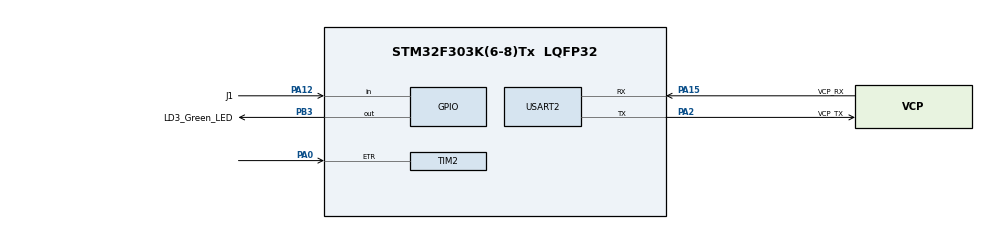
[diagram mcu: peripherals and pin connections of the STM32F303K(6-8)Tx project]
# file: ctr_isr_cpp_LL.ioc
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Mcu.Family=STM32F3
Mcu.Name=STM32F303K(6-8)Tx
Mcu.Package=LQFP32
NVIC.PriorityGroup=NVIC_PRIORITYGROUP_4
NVIC.TIM2_IRQn=true\:0\:0\:false\:false\:true\:true\:true
PA0.GPIO_PuPd=GPIO_PULLDOWN
PA0.Signal=S_TIM2_CH1_ETR
PA12.GPIO_Label=J1
PA12.GPIO_PuPd=GPIO_PULLUP
PA12.Signal=GPIO_Input
PA13.GPIO_Label=SWDIO
PA13.Mode=Serial_Wire
PA13.Signal=SYS_JTMS-SWDIO
PA14.GPIO_Label=SWCLK
PA14.Mode=Serial_Wire
PA14.Signal=SYS_JTCK-SWCLK
PA15.GPIO_Label=VCP_RX
PA15.Mode=Asynchronous
PA15.Signal=USART2_RX
PA2.GPIO_Label=VCP_TX
PA2.Mode=Asynchronous
PA2.Signal=USART2_TX
PB3.GPIO_Label=LD3_Green_LED
PB3.GPIO_Speed=GPIO_SPEED_FREQ_HIGH
PB3.Signal=GPIO_Output
PF0\ /\ OSC_IN.GPIO_Label=MCO
PF0\ /\ OSC_IN.Mode=HSE-External-Clock-Source
PF0\ /\ OSC_IN.Signal=RCC_OSC_IN
ProjectManager.HeapSize=0x200
ProjectManager.StackSize=0x400
ProjectManager.TargetToolchain=STM32CubeIDE
RCC.AHBFreq_Value=8000000
RCC.APB1Freq_Value=8000000
RCC.APB2Freq_Value=8000000
RCC.CortexFreq_Value=8000000
RCC.HSE_VALUE=8000000
RCC.HSI_VALUE=8000000
RCC.SYSCLKFreq_VALUE=8000000
SH.S_TIM2_CH1_ETR.0=TIM2_ETR,ClockSourceETR_Mode2
TIM2.ClockFilter=15
TIM2.Period=5
USART2.VirtualMode-Asynchronous=VM_ASYNC
board=NUCLEO-F303K8

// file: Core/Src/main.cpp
/* USER CODE BEGIN Header */
/**
  ******************************************************************************
  * @file           : main.cpp
  * @brief          : Main program body
  ******************************************************************************
  * @attention
  *
  * <h2><center>&copy; Copyright (c) 2020 STMicroelectronics.
  * All rights reserved.</center></h2>
  *
  * This software component is licensed by ST under BSD 3-Clause license,
  * the "License"; You may not use this file except in compliance with the
  * License. You may obtain a copy of the License at:
  *                        opensource.org/licenses/BSD-3-Clause
  *
  ******************************************************************************
  Use TIM2 to count a push-button connected between PA0 (called TIM2_ETR) and 3V3.
  PA0 is configured with a pull down.
  Green LED blinks but the blink rate toggles upon each TIM2 interrupt.
  TIM2 interrupt is called after 5 button presses.
  To debounce the button, LL_TIM_ETR_FILTER_FDIV32_N8 is used.
  No HAL - all LL (Low Level).
  */
/* USER CODE END Header */
#include "main.h"

/* USER CODE BEGIN PV */
unsigned ms_cnt;
unsigned tim2_int_cnt;
/* USER CODE END PV */

void SystemClock_Config(void);
static void MX_GPIO_Init(void);
static void MX_USART2_UART_Init(void);
static void MX_TIM2_Init(void);

/* USER CODE BEGIN 0 */
extern "C" void TIM2_IRQHandler(void)
{
  tim2_int_cnt++;
  TIM2->SR   &= ~TIM_SR_UIF;     // Clear prior interrupt
}

/* USER CODE END 0 */

int main(void)
{

  /* MCU Configuration--------------------------------------------------------*/

  /* Reset of all peripherals, Initializes the Flash interface and the Systick. */

  LL_APB2_GRP1_EnableClock(LL_APB2_GRP1_PERIPH_SYSCFG);
  LL_APB1_GRP1_EnableClock(LL_APB1_GRP1_PERIPH_PWR);

  NVIC_SetPriorityGrouping(NVIC_PRIORITYGROUP_4);

  /* System interrupt init*/

  /* Configure the system clock */
  SystemClock_Config();

  /* Initialize all configured peripherals */
  MX_GPIO_Init();
  MX_USART2_UART_Init();
  MX_TIM2_Init();
  /* USER CODE BEGIN 2 */
  SysTick->CTRL |= SysTick_CTRL_TICKINT_Msk;

  //
  // TIM2 setup
  //
  TIM2->ARR   = 5 - 1;           // Set count threshold of 5.
  TIM2->CR1  |= TIM_CR1_CEN;     // Counter enable
  TIM2->SR   &= ~TIM_SR_UIF;     // Clear prior interrupt
  TIM2->DIER |= TIM_DIER_UIE;    // Enable interrupt.
  /* USER CODE END 2 */

  /* Infinite loop */
  /* USER CODE BEGIN WHILE */
  while (1)
  {
	bool b = tim2_int_cnt & 1; // 0!=(TIM2_ETR_GPIO_Port->IDR & TIM2_ETR_Pin);
	uint32_t x = ms_cnt >> (b ? 5 : 9);
    (x & 1 ? LD3_Green_LED_GPIO_Port->BSRR : LD3_Green_LED_GPIO_Port->BRR) = LD3_Green_LED_Pin;
    /* USER CODE END WHILE */

  }
}

void SystemClock_Config(void)
{
  LL_FLASH_SetLatency(LL_FLASH_LATENCY_0);
  while(LL_FLASH_GetLatency()!= LL_FLASH_LATENCY_0)
  {
  }
  LL_RCC_HSI_Enable();

   /* Wait till HSI is ready */
  while(LL_RCC_HSI_IsReady() != 1)
  {

  }
  LL_RCC_HSI_SetCalibTrimming(16);
  LL_RCC_SetAHBPrescaler(LL_RCC_SYSCLK_DIV_1);
  LL_RCC_SetAPB1Prescaler(LL_RCC_APB1_DIV_1);
  LL_RCC_SetAPB2Prescaler(LL_RCC_APB1_DIV_1);
  LL_RCC_SetSysClkSource(LL_RCC_SYS_CLKSOURCE_HSI);

   /* Wait till System clock is ready */
  while(LL_RCC_GetSysClkSource() != LL_RCC_SYS_CLKSOURCE_STATUS_HSI)
  {

  }
  LL_Init1msTick(8000000);
  LL_SetSystemCoreClock(8000000);
}

static void MX_TIM2_Init(void)
{

  LL_TIM_InitTypeDef TIM_InitStruct = {0};

  LL_GPIO_InitTypeDef GPIO_InitStruct = {0};

  /* Peripheral clock enable */
  LL_APB1_GRP1_EnableClock(LL_APB1_GRP1_PERIPH_TIM2);

  LL_AHB1_GRP1_EnableClock(LL_AHB1_GRP1_PERIPH_GPIOA);
  /**TIM2 GPIO Configuration
  PA0   ------> TIM2_ETR
  */
  GPIO_InitStruct.Pin = LL_GPIO_PIN_0;
  GPIO_InitStruct.Mode = LL_GPIO_MODE_ALTERNATE;
  GPIO_InitStruct.Speed = LL_GPIO_SPEED_FREQ_LOW;
  GPIO_InitStruct.OutputType = LL_GPIO_OUTPUT_PUSHPULL;
  GPIO_InitStruct.Pull = LL_GPIO_PULL_DOWN;
  GPIO_InitStruct.Alternate = LL_GPIO_AF_1;
  LL_GPIO_Init(GPIOA, &GPIO_InitStruct);

  /* TIM2 interrupt Init */
  NVIC_SetPriority(TIM2_IRQn, NVIC_EncodePriority(NVIC_GetPriorityGrouping(),0, 0));
  NVIC_EnableIRQ(TIM2_IRQn);

  TIM_InitStruct.Prescaler = 0;
  TIM_InitStruct.CounterMode = LL_TIM_COUNTERMODE_UP;
  TIM_InitStruct.Autoreload = 5;
  TIM_InitStruct.ClockDivision = LL_TIM_CLOCKDIVISION_DIV1;
  LL_TIM_Init(TIM2, &TIM_InitStruct);
  LL_TIM_DisableARRPreload(TIM2);
  LL_TIM_ConfigETR(TIM2, LL_TIM_ETR_POLARITY_NONINVERTED, LL_TIM_ETR_PRESCALER_DIV1, LL_TIM_ETR_FILTER_FDIV32_N8);
  LL_TIM_SetClockSource(TIM2, LL_TIM_CLOCKSOURCE_EXT_MODE2);
  LL_TIM_SetTriggerOutput(TIM2, LL_TIM_TRGO_RESET);
  LL_TIM_DisableMasterSlaveMode(TIM2);

}

static void MX_USART2_UART_Init(void)
{

  LL_USART_InitTypeDef USART_InitStruct = {0};

  LL_GPIO_InitTypeDef GPIO_InitStruct = {0};

  /* Peripheral clock enable */
  LL_APB1_GRP1_EnableClock(LL_APB1_GRP1_PERIPH_USART2);

  LL_AHB1_GRP1_EnableClock(LL_AHB1_GRP1_PERIPH_GPIOA);
  /**USART2 GPIO Configuration
  PA2   ------> USART2_TX
  PA15   ------> USART2_RX
  */
  GPIO_InitStruct.Pin = VCP_TX_Pin|VCP_RX_Pin;
  GPIO_InitStruct.Mode = LL_GPIO_MODE_ALTERNATE;
  GPIO_InitStruct.Speed = LL_GPIO_SPEED_FREQ_HIGH;
  GPIO_InitStruct.OutputType = LL_GPIO_OUTPUT_PUSHPULL;
  GPIO_InitStruct.Pull = LL_GPIO_PULL_NO;
  GPIO_InitStruct.Alternate = LL_GPIO_AF_7;
  LL_GPIO_Init(GPIOA, &GPIO_InitStruct);

  USART_InitStruct.BaudRate = 38400;
  USART_InitStruct.DataWidth = LL_USART_DATAWIDTH_8B;
  USART_InitStruct.StopBits = LL_USART_STOPBITS_1;
  USART_InitStruct.Parity = LL_USART_PARITY_NONE;
  USART_InitStruct.TransferDirection = LL_USART_DIRECTION_TX_RX;
  USART_InitStruct.HardwareFlowControl = LL_USART_HWCONTROL_NONE;
  USART_InitStruct.OverSampling = LL_USART_OVERSAMPLING_16;
  LL_USART_Init(USART2, &USART_InitStruct);
  LL_USART_DisableIT_CTS(USART2);
  LL_USART_ConfigAsyncMode(USART2);
  LL_USART_Enable(USART2);

}

static void MX_GPIO_Init(void)
{
  LL_GPIO_InitTypeDef GPIO_InitStruct = {0};

  /* GPIO Ports Clock Enable */
  LL_AHB1_GRP1_EnableClock(LL_AHB1_GRP1_PERIPH_GPIOF);
  LL_AHB1_GRP1_EnableClock(LL_AHB1_GRP1_PERIPH_GPIOA);
  LL_AHB1_GRP1_EnableClock(LL_AHB1_GRP1_PERIPH_GPIOB);

  /**/
  LL_GPIO_ResetOutputPin(LD3_Green_LED_GPIO_Port, LD3_Green_LED_Pin);

  /**/
  GPIO_InitStruct.Pin = J1_Pin;
  GPIO_InitStruct.Mode = LL_GPIO_MODE_INPUT;
  GPIO_InitStruct.Pull = LL_GPIO_PULL_UP;
  LL_GPIO_Init(J1_GPIO_Port, &GPIO_InitStruct);

  /**/
  GPIO_InitStruct.Pin = LD3_Green_LED_Pin;
  GPIO_InitStruct.Mode = LL_GPIO_MODE_OUTPUT;
  GPIO_InitStruct.Speed = LL_GPIO_SPEED_FREQ_HIGH;
  GPIO_InitStruct.OutputType = LL_GPIO_OUTPUT_PUSHPULL;
  GPIO_InitStruct.Pull = LL_GPIO_PULL_NO;
  LL_GPIO_Init(LD3_Green_LED_GPIO_Port, &GPIO_InitStruct);

}

void Error_Handler(void)
{
}

/************************ (C) COPYRIGHT STMicroelectronics *****END OF FILE****/
